# earlgrey register map
Vendor: lowRISC; File version: 0.1
CPU: ibex rev01, little endian, no MPU, no FPU, VTOR, 2 interrupt priority bits, 2 interrupts
Registers are 32-bit, read-write, no defined reset value unless marked. A register's access mark holds for its fields unless they carry their own. Offsets are from the block's base; [hi:lo] are bit positions.

## SPI_HOST0 — Serial peripheral interface for host mode, suitable for interfacing external serial NOR flash devices
Base 0x40300000
Same registers: SPI_HOST1 0x40310000
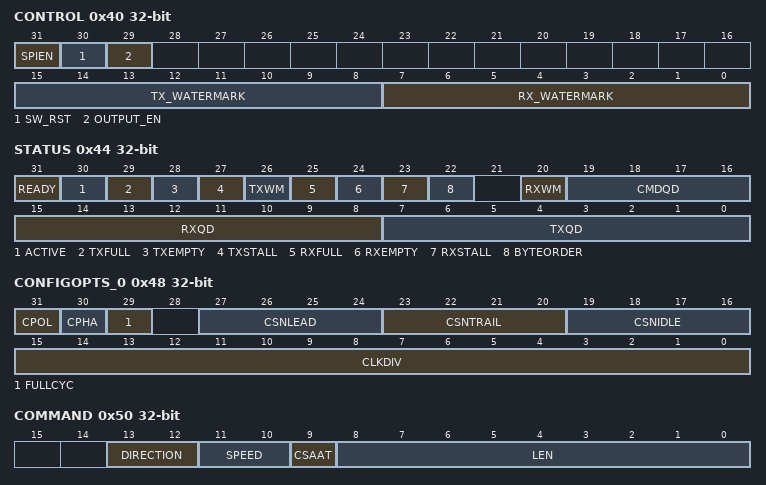
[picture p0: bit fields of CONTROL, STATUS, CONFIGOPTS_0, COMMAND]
0x40 CONTROL
  [31] SPIEN — Enables the SPI host. On reset, this field is 0, meaning that no transactions can proceed.
  [30] SW_RST — Clears the entire IP to the reset state when set to 1, including the FIFOs, the CDC's, the core state machine and the shift register. In the current implementation, the CDC FIFOs are drained not reset. Therefore software must confirm that both FIFO's empty before releasing the IP from reset.
  [29] OUTPUT_EN — Enable the SPI host output buffers for the sck, csb, and sd lines. This allows the SPI_HOST IP to connect to the same bus as other SPI controllers without interference.
  [15:8] TX_WATERMARK — If !!EVENT_ENABLE.TXWM is set, the IP will send an interrupt when the depth of the TX FIFO drops below TX_WATERMARK words (32b each).
  [7:0] RX_WATERMARK — If !!EVENT_ENABLE.RXWM is set, the IP will send an interrupt when the depth of the RX FIFO reaches RX_WATERMARK words (32b each).
0x44 STATUS ro
  [31] READY — When high, indicates the SPI host is ready to receive commands. Writing to COMMAND when READY is low is an error, and will trigger an interrupt.
  [30] ACTIVE — When high, indicates the SPI host is processing a previously issued command.
  [29] TXFULL — When high, indicates that the transmit data fifo is full. Any further writes to !!RXDATA will create an error interrupt.
  [28] TXEMPTY — When high, indicates that the transmit data fifo is empty. Note, one transmit item can be pending in the internal transmit datapath (inside the spi_host_byte_select module). This means the transmit data fifo is empty and TXEMTPY will be high, while there is still one packet that needs to be transmitted.
  [27] TXSTALL — If high, signifies that an ongoing transaction has stalled due to lack of data in the TX FIFO
  [26] TXWM — If high, the amount of data in the TX FIFO has fallen below the level of !!CONTROL.TX_WATERMARK words (32b each).
  [25] RXFULL — When high, indicates that the receive fifo is full. Any ongoing transactions will stall until firmware reads some data from !!RXDATA.
  [24] RXEMPTY — When high, indicates that the receive fifo is empty. Any reads from RX FIFO will cause an error interrupt.
  [23] RXSTALL — If high, signifies that an ongoing transaction has stalled due to lack of available space in the RX FIFO
  [22] BYTEORDER — The value of the ByteOrder parameter, provided so that firmware can confirm proper IP configuration.
  [20] RXWM — If high, the number of 32-bits in the RX FIFO now exceeds the !!CONTROL.RX_WATERMARK entries (32b each).
  [19:16] CMDQD — Command queue depth. Indicates how many unread 32-bit words are currently in the command segment queue.
  [15:8] RXQD — Receive queue depth. Indicates how many unread 32-bit words are currently in the RX FIFO. When active, this result may an underestimate due to synchronization delays.
  [7:0] TXQD — Transmit queue depth. Indicates how many unsent 32-bit words are currently in the TX FIFO. When active, this result may be an overestimate due to synchronization delays. It may also be an underestimate by 1 because of one pending transmit packet in the internal transmit datapath (inside the spi_host_byte_select module).
0x48 CONFIGOPTS_0 — Configuration options register. Contains options for controlling each peripheral. One register per cs_n line
  [31] CPOL — The polarity of the sck clock signal. When CPOL is 0, sck is low when idle, and emits high pulses. When CPOL is 1, sck is high when idle, and emits a series of low pulses.
  [30] CPHA — The phase of the sck clock signal relative to the data. When CPHA = 0, the data changes on the trailing edge of sck and is typically sampled on the leading edge. Conversely if CPHA = 1 high, data lines change on the leading edge of sck and are typically sampled on the trailing edge. CPHA should be chosen to match the phase of the selected device. The sampling behavior is modified by the !!CONFIGOPTS.FULLCYC bit.
  [29] FULLCYC — Full cycle. Modifies the CPHA sampling behaviour to allow for longer device logic setup times. Rather than sampling the SD bus a half cycle after shifting out data, the data is sampled a full cycle after shifting data out. This means that if CPHA = 0, data is shifted out on the trailing edge, and sampled a full cycle later. If CPHA = 1, data is shifted and sampled with the trailing edge, also separated by a full cycle.
  [27:24] CSNLEAD — CS_N Leading Time. Indicates the number of half sck cycles, CSNLEAD+1, to leave between the falling edge of cs_n and the first edge of sck. Setting this register to zero corresponds to the minimum delay of one-half sck cycle
  [23:20] CSNTRAIL — CS_N Trailing Time. Indicates the number of half sck cycles, CSNTRAIL+1, to leave between last edge of sck and the rising edge of cs_n. Setting this register to zero corresponds to the minimum delay of one-half sck cycle.
  [19:16] CSNIDLE — Minimum idle time between commands. Indicates the minimum number of sck half-cycles to hold cs_n high between commands. Setting this register to zero creates a minimally-wide CS_N-high pulse of one-half sck cycle.
  [15:0] CLKDIV — Core clock divider. Slows down subsequent SPI transactions by a factor of (CLKDIV+1) relative to the core clock frequency. The period of sck, T(sck) then becomes `2*(CLK_DIV+1)*T(core)`
0x4C CSID — Chip-Select ID Controls which device to target with the next command. This register is passed to the core whenever !!COMMAND is written. The core then asserts cio_csb_o[!!CSID] during the execution of the command.
  [31:0] CSID — Chip Select ID
0x50 COMMAND wo — Command Register Parameters specific to each command segment. Unlike the !!CONFIGOPTS multi-register, there is only one command register for controlling all attached SPI devices
  [13:12] DIRECTION — The direction for the following command: "0" = Dummy cycles (no TX/RX). "1" = Rx only, "2" = Tx only, "3" = Bidirectional Tx/Rx (Standard SPI mode only).
  [11:10] SPEED — The speed for this command segment: "0" = Standard SPI. "1" = Dual SPI. "2"=Quad SPI, "3": RESERVED.
  [9] CSAAT — Chip select active after transaction. If CSAAT = 0, the chip select line is raised immediately at the end of the command segment. If !!COMMAND.CSAAT = 1, the chip select line is left low at the end of the current transaction segment. This allows the creation longer, more complete SPI transactions, consisting of several separate segments for issuing instructions, pausing for dummy cycles, and transmitting or receiving data from the device.
  [8:0] LEN — Segment Length. For read or write segments, this field controls the number of 1-byte bursts to transmit and or receive in this command segment. The number of cyles required to send or received a byte will depend on !!COMMAND.SPEED. For dummy segments, (!!COMMAND.DIRECTION == 0), this register controls the number of dummy cycles to issue. The number of bytes (or dummy cycles) in the segment will be equal to !!COMMAND.LEN + 1.
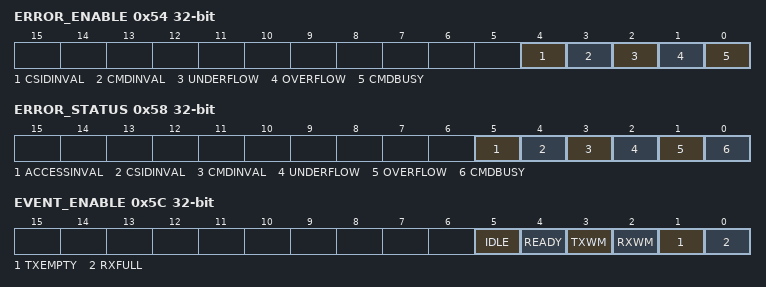
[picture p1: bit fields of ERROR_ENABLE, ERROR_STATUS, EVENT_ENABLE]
0x54 ERROR_ENABLE — Controls which classes of errors raise an interrupt.
  [4] CSIDINVAL — Invalid CSID: If this bit is set, the block sends an error interrupt whenever a command is submitted, but CSID exceeds NumCS.
  [3] CMDINVAL — Invalid Command Errors: If this bit is set, the block sends an error interrupt whenever a command is sent with invalid values for !!COMMAND.SPEED or !!COMMAND.DIRECTION.
  [2] UNDERFLOW — Underflow Errors: If this bit is set, the block sends an error interrupt whenever there is a read from !!RXDATA but the RX FIFO is empty.
  [1] OVERFLOW — Overflow Errors: If this bit is set, the block sends an error interrupt whenever the TX FIFO overflows.
  [0] CMDBUSY — Command Error: If this bit is set, the block sends an error interrupt whenever a command is issued while busy (i.e. a 1 is when !!STATUS.READY is not asserted.)
0x58 ERROR_STATUS — Indicates that any errors that have occurred. When an error occurs, the corresponding bit must be cleared here before issuing any further commands.
  [5] ACCESSINVAL — Indicates that TLUL attempted to write to TXDATA with no bytes enabled. Such 'zero byte' writes are not supported.
  [4] CSIDINVAL — Indicates a command was attempted with an invalid value for !!CSID.
  [3] CMDINVAL — Indicates an invalid command segment, meaning either an invalid value of !!COMMAND.SPEED or a request for bidirectional data transfer at dual or quad speed
  [2] UNDERFLOW — Indicates that firmware has attempted to read from !!RXDATA when the RX FIFO is empty.
  [1] OVERFLOW — Indicates that firmware has overflowed the TX FIFO
  [0] CMDBUSY — Indicates a write to !!COMMAND when !!STATUS.READY = 0.
0x5C EVENT_ENABLE — Controls which classes of SPI events raise an interrupt.
  [5] IDLE — Assert to send a spi_event interrupt whenever !!STATUS.ACTIVE goes low
  [4] READY — Assert to send a spi_event interrupt whenever !!STATUS.READY goes high
  [3] TXWM — Assert to send a spi_event interrupt whenever the number of 32-bit words in the TX FIFO is less than !!CONTROL.TX_WATERMARK. To prevent the reassertion of this interrupt add more data to the TX FIFO, or reduce !!CONTROL.TX_WATERMARK.
  [2] RXWM — Assert to send a spi_event interrupt whenever the number of 32-bit words in the RX FIFO is greater than !!CONTROL.RX_WATERMARK. To prevent the reassertion of this interrupt, read more data from the RX FIFO, or increase !!CONTROL.RX_WATERMARK.
  [1] TXEMPTY — Assert to send a spi_event interrupt whenever !!STATUS.TXEMPTY goes high
  [0] RXFULL — Assert to send a spi_event interrupt whenever !!STATUS.RXFULL goes high
